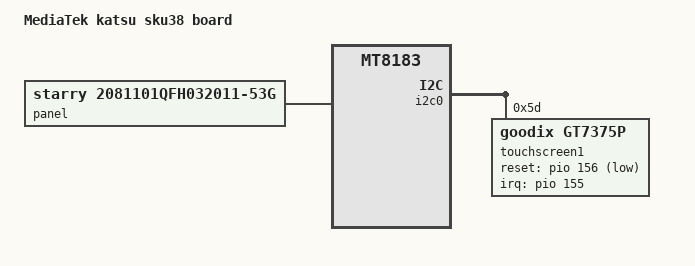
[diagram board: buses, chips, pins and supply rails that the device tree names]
// SPDX-License-Identifier: (GPL-2.0 OR MIT)
/*
 * Copyright 2021 Google LLC
 */

/dts-v1/;
#include "mt8183-kukui-kakadu.dtsi"
#include "mt8183-kukui-audio-rt1015p.dtsi"

/ {
	model = "MediaTek katsu sku38 board";
	compatible = "google,katsu-sku38", "google,katsu",
				"mediatek,mt8183";
};

&i2c0 {
	status = "okay";

	/delete-node/touchscreen@10;
	touchscreen1: touchscreen@5d {
		compatible = "goodix,gt7375p";
		reg = <0x5d>;
		pinctrl-names = "default";
		pinctrl-0 = <&open_touch>;

		interrupt-parent = <&pio>;
		interrupts = <155 IRQ_TYPE_LEVEL_LOW>;

		reset-gpios = <&pio 156 GPIO_ACTIVE_LOW>;
	};
};

&panel {
	compatible = "starry,2081101qfh032011-53g";
};

&sound {
	compatible = "mediatek,mt8183_mt6358_ts3a227_rt1015p";
};
